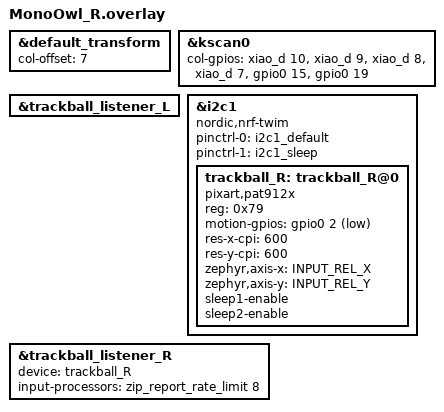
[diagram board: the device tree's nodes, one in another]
#include "MonoOwl.dtsi"
#include <dt-bindings/zmk/input_transform.h>
#include <input/processors.dtsi>

&default_transform {
    col-offset = <7>;
};

&kscan0 {
        col-gpios
            = <&xiao_d 10 (GPIO_ACTIVE_HIGH)>
            , <&xiao_d 9 (GPIO_ACTIVE_HIGH)>
            , <&xiao_d 8 (GPIO_ACTIVE_HIGH)>
            , <&xiao_d 7 (GPIO_ACTIVE_HIGH)>
            , <&gpio0 15 (GPIO_ACTIVE_HIGH)>
            , <&gpio0 19 (GPIO_ACTIVE_HIGH)>
            ;
};

&trackball_listener_L {
    status = "okay";
};

&i2c1 {
	status = "okay";
	compatible = "nordic,nrf-twim";
	pinctrl-0 = <&i2c1_default>;
	pinctrl-1 = <&i2c1_sleep>;
	pinctrl-names = "default", "sleep";

	trackball_R: trackball_R@0 {
		compatible = "pixart,pat912x";
		reg = <0x79>;
		status = "okay";
		motion-gpios = <&gpio0 2 (GPIO_ACTIVE_LOW | GPIO_PULL_UP)>;
		res-x-cpi = <600>;
		res-y-cpi = <600>;
		zephyr,axis-x = <INPUT_REL_X>;
		zephyr,axis-y = <INPUT_REL_Y>;
		sleep1-enable;
		sleep2-enable;
	};
};

&trackball_listener_R {
    status = "okay";
    device = <&trackball_R>;
	input-processors = <&zip_report_rate_limit 8>;
};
